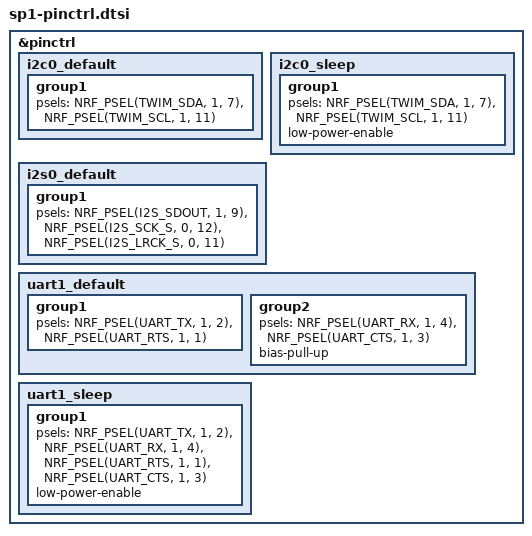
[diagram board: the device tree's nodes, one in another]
&pinctrl {
	i2c0_default: i2c0_default {
		group1 {
			psels = <NRF_PSEL(TWIM_SDA, 1, 7)>,
				<NRF_PSEL(TWIM_SCL, 1, 11)>;
		};
	};
	i2c0_sleep: i2c0_sleep {
		group1 {
			psels = <NRF_PSEL(TWIM_SDA, 1, 7)>,
				<NRF_PSEL(TWIM_SCL, 1, 11)>;
			low-power-enable;
		};
	};
	i2s0_default: i2s0_default {
		group1 {
			psels = <NRF_PSEL(I2S_SDOUT, 1, 9)>,
				<NRF_PSEL(I2S_SCK_S, 0, 12)>,
				<NRF_PSEL(I2S_LRCK_S, 0, 11)>;
		};
	};
	/* UART to the onboard Infineon CYW20706 Bluetooth module. Pins verified
	 * against community reverse-engineering of this same board
	 * (bnjreece/feldd-sp1-firmware, real hardware capture): TX=P1.02,
	 * RX=P1.04, RTS=P1.01, CTS=P1.03. Module reset (P0.10, active-low) is
	 * handled separately as raw GPIO -- see battery.c-style modules for the
	 * NFC-pin GPIO reclaim already done in sp1.dts. */
	uart1_default: uart1_default {
		group1 {
			psels = <NRF_PSEL(UART_TX, 1, 2)>,
				<NRF_PSEL(UART_RTS, 1, 1)>;
		};
		group2 {
			psels = <NRF_PSEL(UART_RX, 1, 4)>,
				<NRF_PSEL(UART_CTS, 1, 3)>;
			bias-pull-up;
		};
	};
	uart1_sleep: uart1_sleep {
		group1 {
			psels = <NRF_PSEL(UART_TX, 1, 2)>,
				<NRF_PSEL(UART_RX, 1, 4)>,
				<NRF_PSEL(UART_RTS, 1, 1)>,
				<NRF_PSEL(UART_CTS, 1, 3)>;
			low-power-enable;
		};
	};
};
